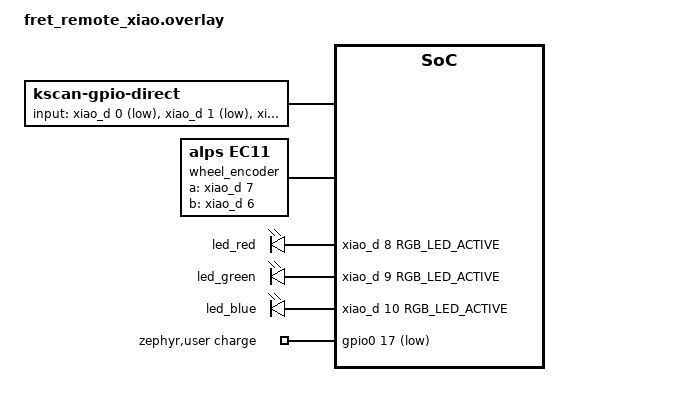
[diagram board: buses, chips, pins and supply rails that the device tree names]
#include <dt-bindings/zmk/matrix_transform.h>

/*
 * FRET Remote V1 - Seeed XIAO nRF52840 mit ANO-Rad
 *
 *   D0   Play/Pause      (ANO Mitte)
 *   D1   "+"             (ANO oben)
 *   D2   Zurueck         (ANO links)
 *   D3   "-"             (ANO unten)
 *   D4   Weiter          (ANO rechts)
 *   D5   frei (Reserve, analogfaehig)
 *   D6   Rad ENB
 *   D7   Rad ENA         Rad = Lauter / Leiser
 *   D8   RGB-LED rot
 *   D9   RGB-LED gruen
 *   D10  RGB-LED blau
 *
 *   ANO COMA/COMB an GND, gemeinsame Anode der RGB-LED an 3V3.
 *
 *   Ladeanzeige: P0.17 ist auf dem XIAO fest mit dem CHG-Ausgang des
 *   Ladereglers verbunden (LOW = Akku wird geladen). Kein Rand-Pin noetig.
 */

/* Gemeinsame Anode -> Farbe leuchtet bei LOW */
#define RGB_LED_ACTIVE GPIO_ACTIVE_LOW

/* D6/D7 (UART) und D8-D10 (SPI) werden nur als normale Pins benutzt.
 * UART schaltet ZMK fuer den XIAO schon selbst ab, SPI und I2C hier
 * zur Sicherheit auch, damit nichts auf Rad oder LED funkt. */
&xiao_spi { status = "disabled"; };
&xiao_i2c { status = "disabled"; };

/ {
    chosen {
        zmk,kscan = &kscan;
        zmk,matrix-transform = &default_transform;
    };

    /* Reihenfolge = Tastenposition in der Keymap:
     * 0 Play, 1 Oben (+), 2 Zurueck, 3 Unten (-), 4 Weiter */
    kscan: kscan {
        compatible = "zmk,kscan-gpio-direct";
        wakeup-source;

        input-gpios
            = <&xiao_d 0 (GPIO_ACTIVE_LOW | GPIO_PULL_UP)>
            , <&xiao_d 1 (GPIO_ACTIVE_LOW | GPIO_PULL_UP)>
            , <&xiao_d 2 (GPIO_ACTIVE_LOW | GPIO_PULL_UP)>
            , <&xiao_d 3 (GPIO_ACTIVE_LOW | GPIO_PULL_UP)>
            , <&xiao_d 4 (GPIO_ACTIVE_LOW | GPIO_PULL_UP)>
            ;
    };

    default_transform: default_transform {
        compatible = "zmk,matrix-transform";
        columns = <5>;
        rows = <1>;

        map = <
            RC(0,0) RC(0,1) RC(0,2) RC(0,3) RC(0,4)
        >;
    };

    /* ANO-Rad: 24 Rastungen pro Umdrehung, 4 Signalwechsel je Rastung
     * -> pro Rastung genau ein Lauter/Leiser (gleiches Verhaeltnis wie
     * beim Clone). Falsche Drehrichtung: in der Keymap die beiden
     * Werte bei sensor-bindings tauschen. */
    wheel_encoder: wheel_encoder {
        compatible = "alps,ec11";
        a-gpios = <&xiao_d 7 (GPIO_ACTIVE_HIGH | GPIO_PULL_UP)>;
        b-gpios = <&xiao_d 6 (GPIO_ACTIVE_HIGH | GPIO_PULL_UP)>;
        steps = <96>;
        status = "okay";
    };

    sensors: sensors {
        compatible = "zmk,keymap-sensors";
        sensors = <&wheel_encoder>;
        triggers-per-rotation = <24>;
    };

    /* Status-RGB-LED (siehe src/status_led.c) */
    status_leds {
        compatible = "gpio-leds";
        led_red: led_red {
            gpios = <&xiao_d 8 RGB_LED_ACTIVE>;
        };
        led_green: led_green {
            gpios = <&xiao_d 9 RGB_LED_ACTIVE>;
        };
        led_blue: led_blue {
            gpios = <&xiao_d 10 RGB_LED_ACTIVE>;
        };
    };

    /* Ladezustand vom Laderegler (BQ25101 CHG, Open-Drain, LOW = laedt).
     * Wird nur gelesen, solange USB steckt. */
    zephyr,user {
        charge-gpios = <&gpio0 17 (GPIO_ACTIVE_LOW | GPIO_PULL_UP)>;
    };
};
